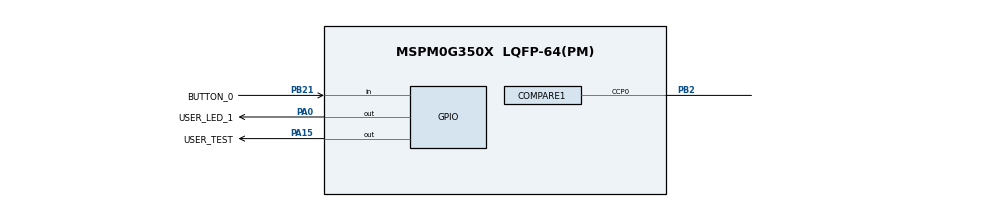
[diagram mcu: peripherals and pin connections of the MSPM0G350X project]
/**
 * @cliArgs --device "MSPM0G350X" --part "Default" --package "LQFP-64(PM)" --product "mspm0_sdk@2.05.01.00"
 * @versions {"tool":"1.25.0+4268"}
 */

/**
 * Import the modules used in this configuration.
 */
const COMPARE  = scripting.addModule("/ti/driverlib/COMPARE", {}, false);
const COMPARE1 = COMPARE.addInstance();
const GPIO     = scripting.addModule("/ti/driverlib/GPIO", {}, false);
const GPIO1    = GPIO.addInstance();

/**
 * Write custom configuration values to the imported modules.
 */
COMPARE1.$name                      = "COMPARE_0";
COMPARE1.timerPeriod                = 5;
COMPARE1.interrupts                 = ["LOAD"];
COMPARE1.peripheral.$assign         = "TIMG6";
COMPARE1.peripheral.ccp0Pin.$assign = "PB2";
COMPARE1.ccp0PinConfig.$name        = "ti_driverlib_gpio_GPIOPinGeneric0";

const Board = scripting.addModule("/ti/driverlib/Board", {}, false);

GPIO1.$name                                 = "GPIO_LEDS";
GPIO1.associatedPins.create(3);
GPIO1.associatedPins[0].$name               = "USER_LED_1";
GPIO1.associatedPins[0].assignedPort        = "PORTA";
GPIO1.associatedPins[0].initialValue        = "SET";
GPIO1.associatedPins[0].pin.$assign         = "PA0";
GPIO1.associatedPins[1].assignedPort        = "PORTA";
GPIO1.associatedPins[1].assignedPortSegment = "Lower";
GPIO1.associatedPins[1].$name               = "USER_TEST";
GPIO1.associatedPins[1].initialValue        = "SET";
GPIO1.associatedPins[1].pin.$assign         = "PA15";
GPIO1.associatedPins[2].$name               = "BUTTON_0";
GPIO1.associatedPins[2].direction           = "INPUT";
GPIO1.associatedPins[2].internalResistor    = "PULL_UP";
GPIO1.associatedPins[2].pin.$assign         = "PB21";

const SYSCTL = scripting.addModule("/ti/driverlib/SYSCTL", {}, false);

/**
 * Pinmux solution for unlocked pins/peripherals. This ensures that minor changes to the automatic solver in a future
 * version of the tool will not impact the pinmux you originally saw.  These lines can be completely deleted in order to
 * re-solve from scratch.
 */
Board.peripheral.$suggestSolution          = "DEBUGSS";
Board.peripheral.swclkPin.$suggestSolution = "PA20";
Board.peripheral.swdioPin.$suggestSolution = "PA19";
SYSCTL.peripheral.$suggestSolution         = "SYSCTL";
